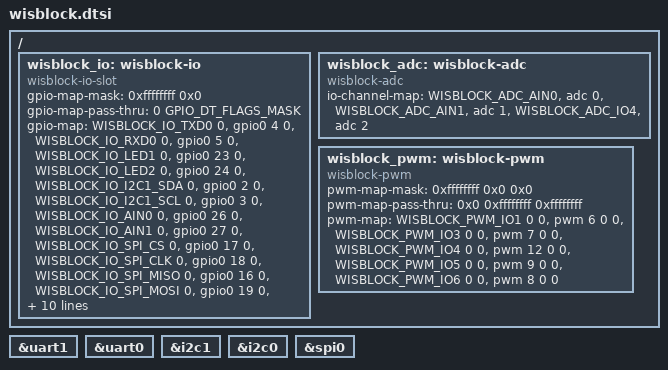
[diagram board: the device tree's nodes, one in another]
/*
 * SPDX-FileCopyrightText: Copyright (c) 2026 RAKwireless Technology Limited
 * SPDX-License-Identifier: Apache-2.0
 */

#include <zephyr/dt-bindings/gpio/wisblock-io-slot.h>
#include <zephyr/dt-bindings/adc/wisblock-adc.h>
#include <zephyr/dt-bindings/pwm/wisblock-pwm.h>

/ {
	wisblock_io: wisblock-io {
		compatible = "wisblock-io-slot";
		#gpio-cells = <2>;
		gpio-map-mask = <0xffffffff 0x0>;
		gpio-map-pass-thru = <0 GPIO_DT_FLAGS_MASK>;
		gpio-map = <WISBLOCK_IO_TXD0 0 &gpio0 4 0>,
			   <WISBLOCK_IO_RXD0 0 &gpio0 5 0>,
			   <WISBLOCK_IO_LED1 0 &gpio0 23 0>,
			   <WISBLOCK_IO_LED2 0 &gpio0 24 0>,
			   <WISBLOCK_IO_I2C1_SDA 0 &gpio0 2 0>,
			   <WISBLOCK_IO_I2C1_SCL 0 &gpio0 3 0>,
			   <WISBLOCK_IO_AIN0 0 &gpio0 26 0>,
			   <WISBLOCK_IO_AIN1 0 &gpio0 27 0>,
			   <WISBLOCK_IO_SPI_CS 0 &gpio0 17 0>,
			   <WISBLOCK_IO_SPI_CLK 0 &gpio0 18 0>,
			   <WISBLOCK_IO_SPI_MISO 0 &gpio0 16 0>,
			   <WISBLOCK_IO_SPI_MOSI 0 &gpio0 19 0>,
			   <WISBLOCK_IO_IO1 0 &gpio0 6 0>,
			   <WISBLOCK_IO_IO2 0 &gpio0 22 0>,
			   <WISBLOCK_IO_IO3 0 &gpio0 7 0>,
			   <WISBLOCK_IO_IO4 0 &gpio0 28 0>,
			   <WISBLOCK_IO_TXD1 0 &gpio0 0 0>,
			   <WISBLOCK_IO_RXD1 0 &gpio0 1 0>,
			   <WISBLOCK_IO_I2C2_SDA 0 &gpio0 20 0>,
			   <WISBLOCK_IO_I2C2_SCL 0 &gpio0 21 0>,
			   <WISBLOCK_IO_IO5 0 &gpio0 9 0>,
			   <WISBLOCK_IO_IO6 0 &gpio0 8 0>;
	};

	wisblock_adc: wisblock-adc {
		compatible = "wisblock-adc";
		#io-channel-cells = <1>;
		io-channel-map = <WISBLOCK_ADC_AIN0 &adc 0>,
				 <WISBLOCK_ADC_AIN1 &adc 1>,
				 <WISBLOCK_ADC_IO4 &adc 2>;
	};

	/*
	 * IO2 is left out: GPIO22 drives the same RP2040 PWM slice 3A as IO1
	 * on GPIO6, so the two cannot carry independent outputs.
	 */
	wisblock_pwm: wisblock-pwm {
		compatible = "wisblock-pwm";
		#pwm-cells = <3>;
		pwm-map-mask = <0xffffffff 0x0 0x0>;
		pwm-map-pass-thru = <0x0 0xffffffff 0xffffffff>;

		pwm-map = <WISBLOCK_PWM_IO1 0 0 &pwm 6 0 0>,
			  <WISBLOCK_PWM_IO3 0 0 &pwm 7 0 0>,
			  <WISBLOCK_PWM_IO4 0 0 &pwm 12 0 0>,
			  <WISBLOCK_PWM_IO5 0 0 &pwm 9 0 0>,
			  <WISBLOCK_PWM_IO6 0 0 &pwm 8 0 0>;
	};
};

wisblock_uart0: &uart1 {};

wisblock_uart1: &uart0 {};

wisblock_i2c1: &i2c1 {};

wisblock_i2c2: &i2c0 {};

wisblock_spi: &spi0 {};
